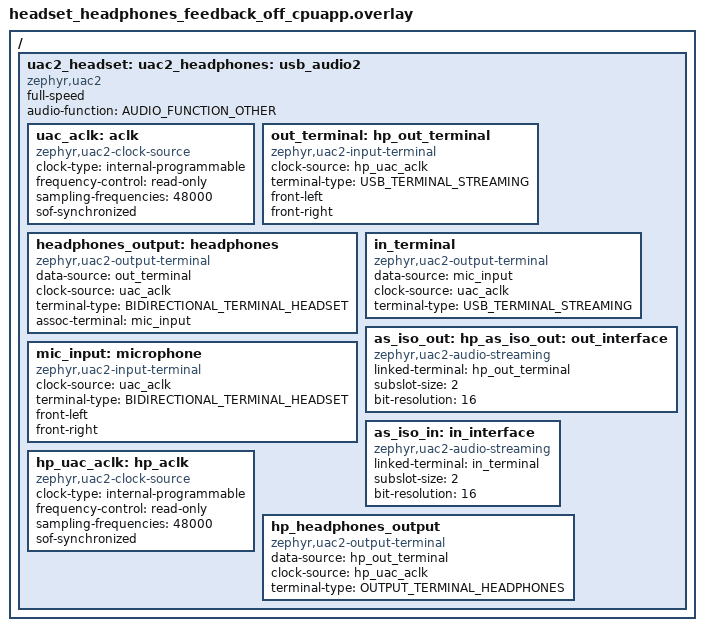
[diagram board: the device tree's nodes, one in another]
/*
 * Copyright (c) 2026 Nordic Semiconductor ASA
 *
 * SPDX-License-Identifier: LicenseRef-Nordic-5-Clause
 */

#include <dt-bindings/usb/audio.h>

/ {
	uac2_headset: usb_audio2 {
		compatible = "zephyr,uac2";
		status = "okay";
		full-speed;
		audio-function = <AUDIO_FUNCTION_HEADSET>;

		uac_aclk: aclk {
			compatible = "zephyr,uac2-clock-source";
			clock-type = "internal-programmable";
			frequency-control = "read-only";
			sampling-frequencies = <48000>;
			sof-synchronized;
		};

		out_terminal: out_terminal {
			compatible = "zephyr,uac2-input-terminal";
			clock-source = <&uac_aclk>;
			terminal-type = <USB_TERMINAL_STREAMING>;
			front-left;
			front-right;
		};

		headphones_output: headphones {
			compatible = "zephyr,uac2-output-terminal";
			data-source = <&out_terminal>;
			clock-source = <&uac_aclk>;
			terminal-type = <BIDIRECTIONAL_TERMINAL_HEADSET>;
			assoc-terminal = <&mic_input>;
		};

		in_terminal: in_terminal {
			compatible = "zephyr,uac2-output-terminal";
			data-source = <&mic_input>;
			clock-source = <&uac_aclk>;
			terminal-type = <USB_TERMINAL_STREAMING>;
		};

		mic_input: microphone {
			compatible = "zephyr,uac2-input-terminal";
			clock-source = <&uac_aclk>;
			terminal-type = <BIDIRECTIONAL_TERMINAL_HEADSET>;
			front-left;
			front-right;
		};

		as_iso_out: out_interface {
			compatible = "zephyr,uac2-audio-streaming";
			linked-terminal = <&out_terminal>;
			subslot-size = <2>;
			bit-resolution = <16>;
		};

		as_iso_in: in_interface {
			compatible = "zephyr,uac2-audio-streaming";
			linked-terminal = <&in_terminal>;
			subslot-size = <2>;
			bit-resolution = <16>;
		};
	};
};

/ {
	uac2_headphones: usb_audio2 {
		compatible = "zephyr,uac2";
		status = "okay";
		full-speed;
		audio-function = <AUDIO_FUNCTION_OTHER>;

		hp_uac_aclk: hp_aclk {
			compatible = "zephyr,uac2-clock-source";
			clock-type = "internal-programmable";
			frequency-control = "read-only";
			sampling-frequencies = <48000>;
			sof-synchronized;
		};

		hp_out_terminal: out_terminal {
			compatible = "zephyr,uac2-input-terminal";
			clock-source = <&hp_uac_aclk>;
			terminal-type = <USB_TERMINAL_STREAMING>;
			front-left;
			front-right;
		};

		hp_headphones_output: hp_headphones_output {
			compatible = "zephyr,uac2-output-terminal";
			data-source = <&hp_out_terminal>;
			clock-source = <&hp_uac_aclk>;
			terminal-type = <OUTPUT_TERMINAL_HEADPHONES>;
		};

		hp_as_iso_out: out_interface {
			compatible = "zephyr,uac2-audio-streaming";
			linked-terminal = <&hp_out_terminal>;
			subslot-size = <2>;
			bit-resolution = <16>;
		};
	};
};
